# STM32U5G9 register map
File version: 1.3
CPU: CM33 r0p1, little endian, MPU, FPU, 4 interrupt priority bits
Registers are 32-bit, read-write, reset 0x0 unless marked. A register's access mark holds for its fields unless they carry their own. Offsets are from the block's base; [hi:lo] are bit positions; {n}, {i} and the like mark numbered series.

## JPEG (part 2 of 3) — JPEG address block description
Base 0x4002A000
Same registers: SEC_JPEG 0x5002A000
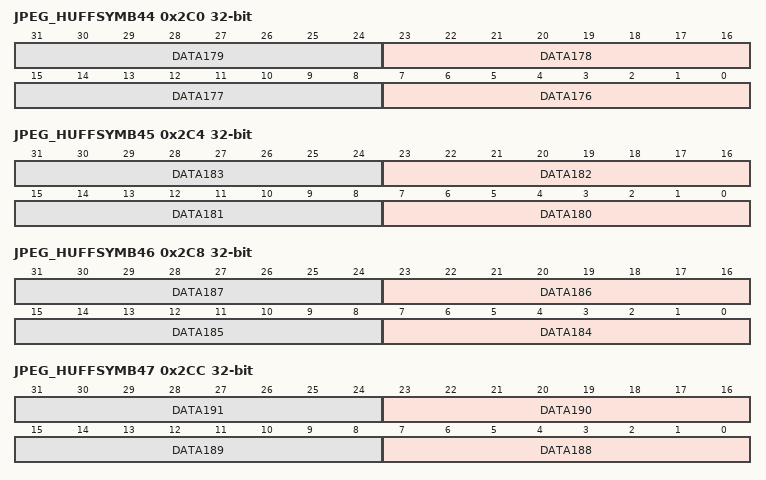
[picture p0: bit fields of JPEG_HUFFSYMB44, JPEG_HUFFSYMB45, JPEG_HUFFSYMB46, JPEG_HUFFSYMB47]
0x2C0 JPEG_HUFFSYMB44 reset not defined — This memory stores the Huffman symbols used internally by the JPEG decoder. The memory content is written by hardware during the header parsing: - DATA0 to DATA161: AC0 symbols - DATA162 to DATA173: DC0 and DC1 symbols - DATA174 to DATA335: AC1 symbols
  [8n-1401:8n-1408] DATA{n} (n=176..179) — Data {n} Huffman symbol.
0x2C4 JPEG_HUFFSYMB45 reset not defined — This memory stores the Huffman symbols used internally by the JPEG decoder. The memory content is written by hardware during the header parsing: - DATA0 to DATA161: AC0 symbols - DATA162 to DATA173: DC0 and DC1 symbols - DATA174 to DATA335: AC1 symbols
  [8n-1433:8n-1440] DATA{n} (n=180..183) — Data {n} Huffman symbol.
0x2C8 JPEG_HUFFSYMB46 reset not defined — This memory stores the Huffman symbols used internally by the JPEG decoder. The memory content is written by hardware during the header parsing: - DATA0 to DATA161: AC0 symbols - DATA162 to DATA173: DC0 and DC1 symbols - DATA174 to DATA335: AC1 symbols
  [8n-1465:8n-1472] DATA{n} (n=184..187) — Data {n} Huffman symbol.
0x2CC JPEG_HUFFSYMB47 reset not defined — This memory stores the Huffman symbols used internally by the JPEG decoder. The memory content is written by hardware during the header parsing: - DATA0 to DATA161: AC0 symbols - DATA162 to DATA173: DC0 and DC1 symbols - DATA174 to DATA335: AC1 symbols
  [8n-1497:8n-1504] DATA{n} (n=188..191) — Data {n} Huffman symbol.
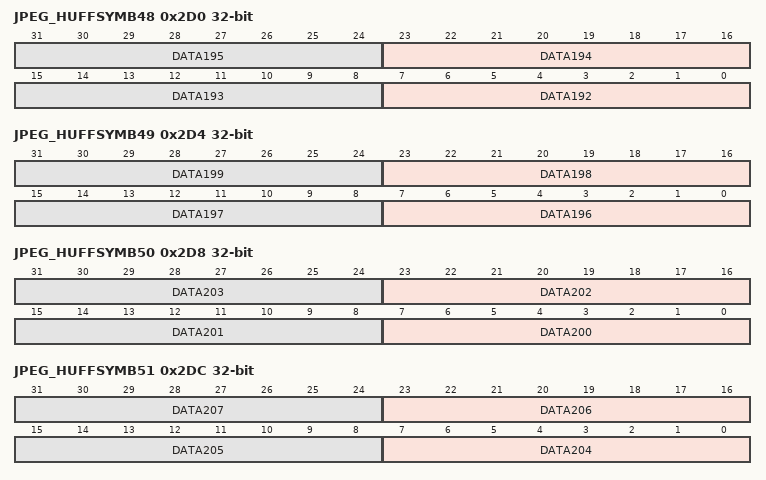
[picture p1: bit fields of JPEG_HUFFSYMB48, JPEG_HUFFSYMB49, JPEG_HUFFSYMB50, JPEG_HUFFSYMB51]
0x2D0 JPEG_HUFFSYMB48 reset not defined — This memory stores the Huffman symbols used internally by the JPEG decoder. The memory content is written by hardware during the header parsing: - DATA0 to DATA161: AC0 symbols - DATA162 to DATA173: DC0 and DC1 symbols - DATA174 to DATA335: AC1 symbols
  [8n-1529:8n-1536] DATA{n} (n=192..195) — Data {n} Huffman symbol.
0x2D4 JPEG_HUFFSYMB49 reset not defined — This memory stores the Huffman symbols used internally by the JPEG decoder. The memory content is written by hardware during the header parsing: - DATA0 to DATA161: AC0 symbols - DATA162 to DATA173: DC0 and DC1 symbols - DATA174 to DATA335: AC1 symbols
  [8n-1561:8n-1568] DATA{n} (n=196..199) — Data {n} Huffman symbol.
0x2D8 JPEG_HUFFSYMB50 reset not defined — This memory stores the Huffman symbols used internally by the JPEG decoder. The memory content is written by hardware during the header parsing: - DATA0 to DATA161: AC0 symbols - DATA162 to DATA173: DC0 and DC1 symbols - DATA174 to DATA335: AC1 symbols
  [8n-1593:8n-1600] DATA{n} (n=200..203) — Data {n} Huffman symbol.
0x2DC JPEG_HUFFSYMB51 reset not defined — This memory stores the Huffman symbols used internally by the JPEG decoder. The memory content is written by hardware during the header parsing: - DATA0 to DATA161: AC0 symbols - DATA162 to DATA173: DC0 and DC1 symbols - DATA174 to DATA335: AC1 symbols
  [8n-1625:8n-1632] DATA{n} (n=204..207) — Data {n} Huffman symbol.
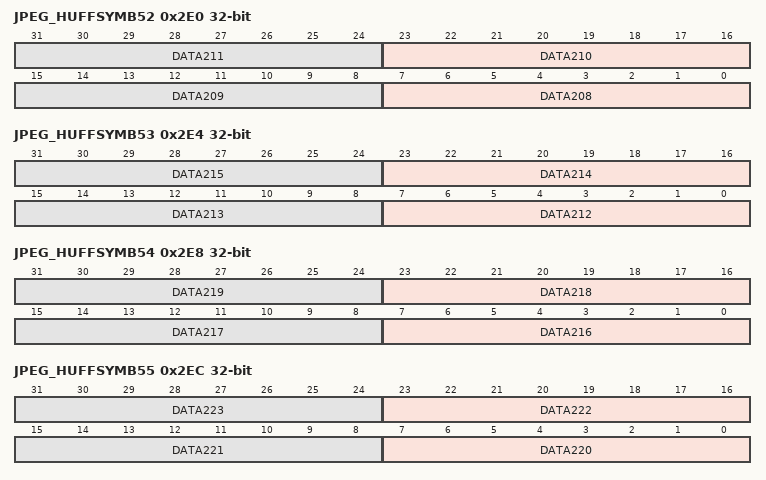
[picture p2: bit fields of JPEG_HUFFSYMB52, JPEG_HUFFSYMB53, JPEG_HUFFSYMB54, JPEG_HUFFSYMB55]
0x2E0 JPEG_HUFFSYMB52 reset not defined — This memory stores the Huffman symbols used internally by the JPEG decoder. The memory content is written by hardware during the header parsing: - DATA0 to DATA161: AC0 symbols - DATA162 to DATA173: DC0 and DC1 symbols - DATA174 to DATA335: AC1 symbols
  [8n-1657:8n-1664] DATA{n} (n=208..211) — Data {n} Huffman symbol.
0x2E4 JPEG_HUFFSYMB53 reset not defined — This memory stores the Huffman symbols used internally by the JPEG decoder. The memory content is written by hardware during the header parsing: - DATA0 to DATA161: AC0 symbols - DATA162 to DATA173: DC0 and DC1 symbols - DATA174 to DATA335: AC1 symbols
  [8n-1689:8n-1696] DATA{n} (n=212..215) — Data {n} Huffman symbol.
0x2E8 JPEG_HUFFSYMB54 reset not defined — This memory stores the Huffman symbols used internally by the JPEG decoder. The memory content is written by hardware during the header parsing: - DATA0 to DATA161: AC0 symbols - DATA162 to DATA173: DC0 and DC1 symbols - DATA174 to DATA335: AC1 symbols
  [8n-1721:8n-1728] DATA{n} (n=216..219) — Data {n} Huffman symbol.
0x2EC JPEG_HUFFSYMB55 reset not defined — This memory stores the Huffman symbols used internally by the JPEG decoder. The memory content is written by hardware during the header parsing: - DATA0 to DATA161: AC0 symbols - DATA162 to DATA173: DC0 and DC1 symbols - DATA174 to DATA335: AC1 symbols
  [8n-1753:8n-1760] DATA{n} (n=220..223) — Data {n} Huffman symbol.
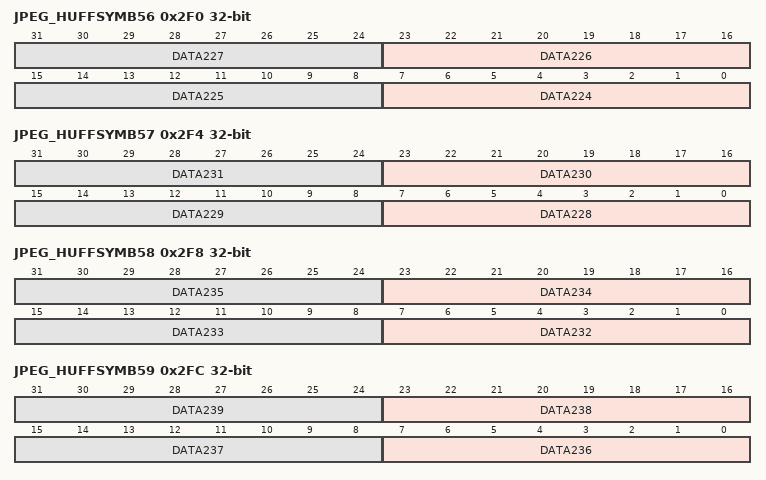
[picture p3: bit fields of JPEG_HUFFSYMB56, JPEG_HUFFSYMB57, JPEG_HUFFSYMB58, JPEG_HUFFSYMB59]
0x2F0 JPEG_HUFFSYMB56 reset not defined — This memory stores the Huffman symbols used internally by the JPEG decoder. The memory content is written by hardware during the header parsing: - DATA0 to DATA161: AC0 symbols - DATA162 to DATA173: DC0 and DC1 symbols - DATA174 to DATA335: AC1 symbols
  [8n-1785:8n-1792] DATA{n} (n=224..227) — Data {n} Huffman symbol.
0x2F4 JPEG_HUFFSYMB57 reset not defined — This memory stores the Huffman symbols used internally by the JPEG decoder. The memory content is written by hardware during the header parsing: - DATA0 to DATA161: AC0 symbols - DATA162 to DATA173: DC0 and DC1 symbols - DATA174 to DATA335: AC1 symbols
  [8n-1817:8n-1824] DATA{n} (n=228..231) — Data {n} Huffman symbol.
0x2F8 JPEG_HUFFSYMB58 reset not defined — This memory stores the Huffman symbols used internally by the JPEG decoder. The memory content is written by hardware during the header parsing: - DATA0 to DATA161: AC0 symbols - DATA162 to DATA173: DC0 and DC1 symbols - DATA174 to DATA335: AC1 symbols
  [8n-1849:8n-1856] DATA{n} (n=232..235) — Data {n} Huffman symbol.
0x2FC JPEG_HUFFSYMB59 reset not defined — This memory stores the Huffman symbols used internally by the JPEG decoder. The memory content is written by hardware during the header parsing: - DATA0 to DATA161: AC0 symbols - DATA162 to DATA173: DC0 and DC1 symbols - DATA174 to DATA335: AC1 symbols
  [8n-1881:8n-1888] DATA{n} (n=236..239) — Data {n} Huffman symbol.
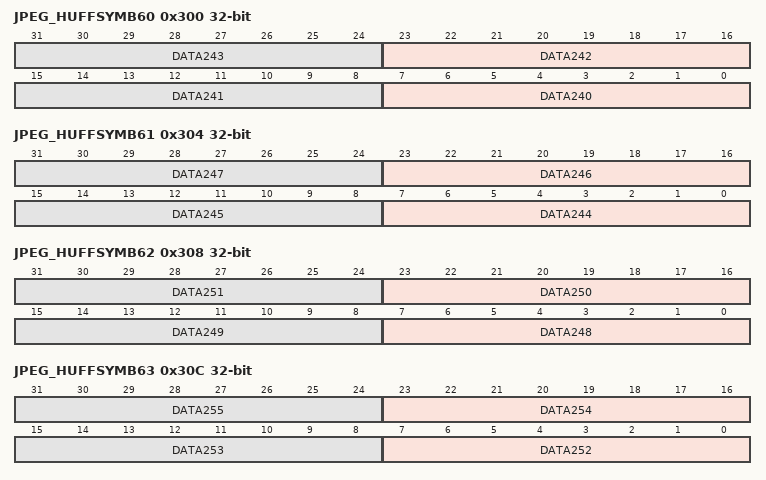
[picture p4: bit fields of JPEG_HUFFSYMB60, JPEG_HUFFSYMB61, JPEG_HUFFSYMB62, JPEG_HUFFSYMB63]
0x300 JPEG_HUFFSYMB60 reset not defined — This memory stores the Huffman symbols used internally by the JPEG decoder. The memory content is written by hardware during the header parsing: - DATA0 to DATA161: AC0 symbols - DATA162 to DATA173: DC0 and DC1 symbols - DATA174 to DATA335: AC1 symbols
  [8n-1913:8n-1920] DATA{n} (n=240..243) — Data {n} Huffman symbol.
0x304 JPEG_HUFFSYMB61 reset not defined — This memory stores the Huffman symbols used internally by the JPEG decoder. The memory content is written by hardware during the header parsing: - DATA0 to DATA161: AC0 symbols - DATA162 to DATA173: DC0 and DC1 symbols - DATA174 to DATA335: AC1 symbols
  [8n-1945:8n-1952] DATA{n} (n=244..247) — Data {n} Huffman symbol.
0x308 JPEG_HUFFSYMB62 reset not defined — This memory stores the Huffman symbols used internally by the JPEG decoder. The memory content is written by hardware during the header parsing: - DATA0 to DATA161: AC0 symbols - DATA162 to DATA173: DC0 and DC1 symbols - DATA174 to DATA335: AC1 symbols
  [8n-1977:8n-1984] DATA{n} (n=248..251) — Data {n} Huffman symbol.
0x30C JPEG_HUFFSYMB63 reset not defined — This memory stores the Huffman symbols used internally by the JPEG decoder. The memory content is written by hardware during the header parsing: - DATA0 to DATA161: AC0 symbols - DATA162 to DATA173: DC0 and DC1 symbols - DATA174 to DATA335: AC1 symbols
  [8n-2009:8n-2016] DATA{n} (n=252..255) — Data {n} Huffman symbol.
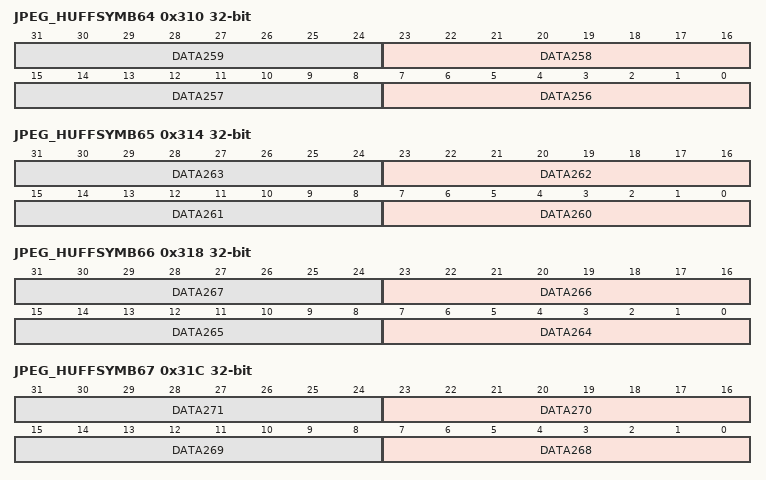
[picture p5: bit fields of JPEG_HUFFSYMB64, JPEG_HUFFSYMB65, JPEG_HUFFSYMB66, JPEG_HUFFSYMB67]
0x310 JPEG_HUFFSYMB64 reset not defined — This memory stores the Huffman symbols used internally by the JPEG decoder. The memory content is written by hardware during the header parsing: - DATA0 to DATA161: AC0 symbols - DATA162 to DATA173: DC0 and DC1 symbols - DATA174 to DATA335: AC1 symbols
  [8n-2041:8n-2048] DATA{n} (n=256..259) — Data {n} Huffman symbol.
0x314 JPEG_HUFFSYMB65 reset not defined — This memory stores the Huffman symbols used internally by the JPEG decoder. The memory content is written by hardware during the header parsing: - DATA0 to DATA161: AC0 symbols - DATA162 to DATA173: DC0 and DC1 symbols - DATA174 to DATA335: AC1 symbols
  [8n-2073:8n-2080] DATA{n} (n=260..263) — Data {n} Huffman symbol.
0x318 JPEG_HUFFSYMB66 reset not defined — This memory stores the Huffman symbols used internally by the JPEG decoder. The memory content is written by hardware during the header parsing: - DATA0 to DATA161: AC0 symbols - DATA162 to DATA173: DC0 and DC1 symbols - DATA174 to DATA335: AC1 symbols
  [8n-2105:8n-2112] DATA{n} (n=264..267) — Data {n} Huffman symbol.
0x31C JPEG_HUFFSYMB67 reset not defined — This memory stores the Huffman symbols used internally by the JPEG decoder. The memory content is written by hardware during the header parsing: - DATA0 to DATA161: AC0 symbols - DATA162 to DATA173: DC0 and DC1 symbols - DATA174 to DATA335: AC1 symbols
  [8n-2137:8n-2144] DATA{n} (n=268..271) — Data {n} Huffman symbol.
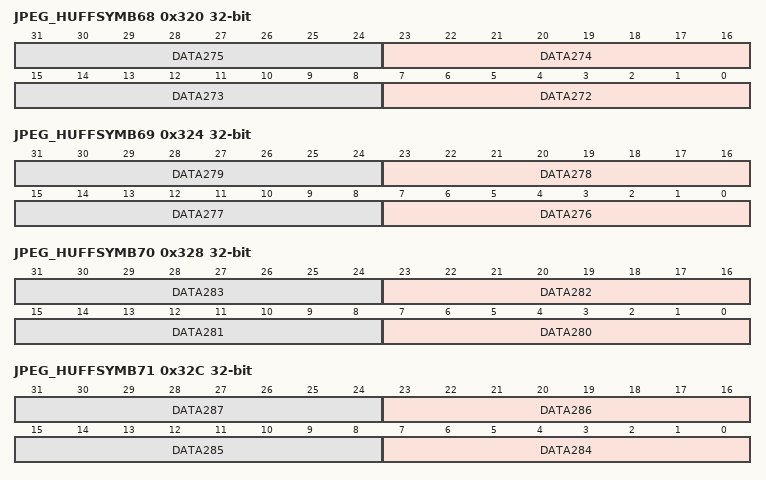
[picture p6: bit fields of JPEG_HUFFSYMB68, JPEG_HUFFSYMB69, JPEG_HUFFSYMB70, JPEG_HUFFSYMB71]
0x320 JPEG_HUFFSYMB68 reset not defined — This memory stores the Huffman symbols used internally by the JPEG decoder. The memory content is written by hardware during the header parsing: - DATA0 to DATA161: AC0 symbols - DATA162 to DATA173: DC0 and DC1 symbols - DATA174 to DATA335: AC1 symbols
  [8n-2169:8n-2176] DATA{n} (n=272..275) — Data {n} Huffman symbol.
0x324 JPEG_HUFFSYMB69 reset not defined — This memory stores the Huffman symbols used internally by the JPEG decoder. The memory content is written by hardware during the header parsing: - DATA0 to DATA161: AC0 symbols - DATA162 to DATA173: DC0 and DC1 symbols - DATA174 to DATA335: AC1 symbols
  [8n-2201:8n-2208] DATA{n} (n=276..279) — Data {n} Huffman symbol.
0x328 JPEG_HUFFSYMB70 reset not defined — This memory stores the Huffman symbols used internally by the JPEG decoder. The memory content is written by hardware during the header parsing: - DATA0 to DATA161: AC0 symbols - DATA162 to DATA173: DC0 and DC1 symbols - DATA174 to DATA335: AC1 symbols
  [8n-2233:8n-2240] DATA{n} (n=280..283) — Data {n} Huffman symbol.
0x32C JPEG_HUFFSYMB71 reset not defined — This memory stores the Huffman symbols used internally by the JPEG decoder. The memory content is written by hardware during the header parsing: - DATA0 to DATA161: AC0 symbols - DATA162 to DATA173: DC0 and DC1 symbols - DATA174 to DATA335: AC1 symbols
  [8n-2265:8n-2272] DATA{n} (n=284..287) — Data {n} Huffman symbol.
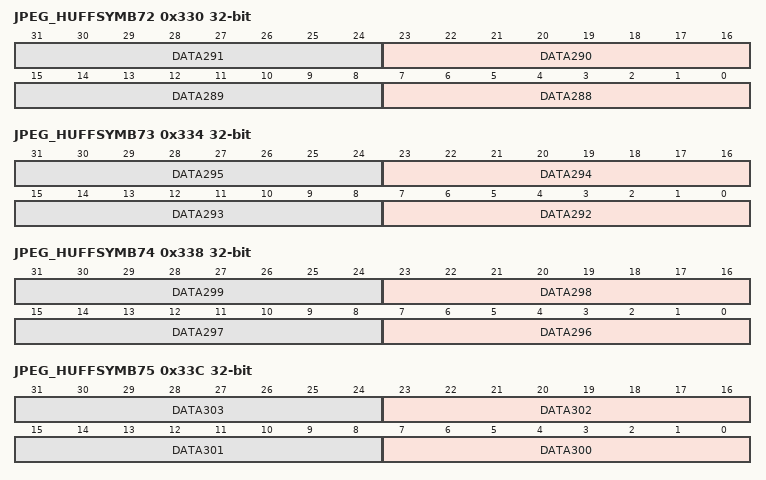
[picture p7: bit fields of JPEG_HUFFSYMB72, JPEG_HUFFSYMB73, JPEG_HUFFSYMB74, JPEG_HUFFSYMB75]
0x330 JPEG_HUFFSYMB72 reset not defined — This memory stores the Huffman symbols used internally by the JPEG decoder. The memory content is written by hardware during the header parsing: - DATA0 to DATA161: AC0 symbols - DATA162 to DATA173: DC0 and DC1 symbols - DATA174 to DATA335: AC1 symbols
  [8n-2297:8n-2304] DATA{n} (n=288..291) — Data {n} Huffman symbol.
0x334 JPEG_HUFFSYMB73 reset not defined — This memory stores the Huffman symbols used internally by the JPEG decoder. The memory content is written by hardware during the header parsing: - DATA0 to DATA161: AC0 symbols - DATA162 to DATA173: DC0 and DC1 symbols - DATA174 to DATA335: AC1 symbols
  [8n-2329:8n-2336] DATA{n} (n=292..295) — Data {n} Huffman symbol.
0x338 JPEG_HUFFSYMB74 reset not defined — This memory stores the Huffman symbols used internally by the JPEG decoder. The memory content is written by hardware during the header parsing: - DATA0 to DATA161: AC0 symbols - DATA162 to DATA173: DC0 and DC1 symbols - DATA174 to DATA335: AC1 symbols
  [8n-2361:8n-2368] DATA{n} (n=296..299) — Data {n} Huffman symbol.
0x33C JPEG_HUFFSYMB75 reset not defined — This memory stores the Huffman symbols used internally by the JPEG decoder. The memory content is written by hardware during the header parsing: - DATA0 to DATA161: AC0 symbols - DATA162 to DATA173: DC0 and DC1 symbols - DATA174 to DATA335: AC1 symbols
  [8n-2393:8n-2400] DATA{n} (n=300..303) — Data {n} Huffman symbol.
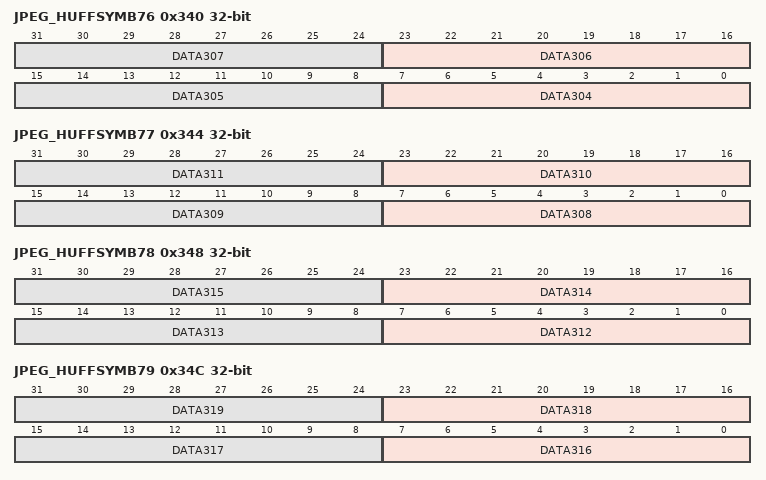
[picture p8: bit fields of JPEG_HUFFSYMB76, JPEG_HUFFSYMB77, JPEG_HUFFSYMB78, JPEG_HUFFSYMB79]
0x340 JPEG_HUFFSYMB76 reset not defined — This memory stores the Huffman symbols used internally by the JPEG decoder. The memory content is written by hardware during the header parsing: - DATA0 to DATA161: AC0 symbols - DATA162 to DATA173: DC0 and DC1 symbols - DATA174 to DATA335: AC1 symbols
  [8n-2425:8n-2432] DATA{n} (n=304..307) — Data {n} Huffman symbol.
0x344 JPEG_HUFFSYMB77 reset not defined — This memory stores the Huffman symbols used internally by the JPEG decoder. The memory content is written by hardware during the header parsing: - DATA0 to DATA161: AC0 symbols - DATA162 to DATA173: DC0 and DC1 symbols - DATA174 to DATA335: AC1 symbols
  [8n-2457:8n-2464] DATA{n} (n=308..311) — Data {n} Huffman symbol.
0x348 JPEG_HUFFSYMB78 reset not defined — This memory stores the Huffman symbols used internally by the JPEG decoder. The memory content is written by hardware during the header parsing: - DATA0 to DATA161: AC0 symbols - DATA162 to DATA173: DC0 and DC1 symbols - DATA174 to DATA335: AC1 symbols
  [8n-2489:8n-2496] DATA{n} (n=312..315) — Data {n} Huffman symbol.
0x34C JPEG_HUFFSYMB79 reset not defined — This memory stores the Huffman symbols used internally by the JPEG decoder. The memory content is written by hardware during the header parsing: - DATA0 to DATA161: AC0 symbols - DATA162 to DATA173: DC0 and DC1 symbols - DATA174 to DATA335: AC1 symbols
  [8n-2521:8n-2528] DATA{n} (n=316..319) — Data {n} Huffman symbol.
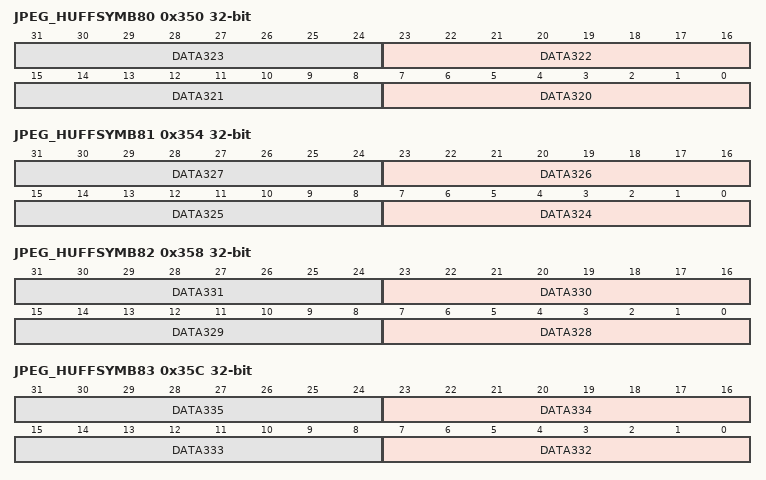
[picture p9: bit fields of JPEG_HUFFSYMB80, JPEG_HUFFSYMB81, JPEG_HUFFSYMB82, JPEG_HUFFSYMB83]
0x350 JPEG_HUFFSYMB80 reset not defined — This memory stores the Huffman symbols used internally by the JPEG decoder. The memory content is written by hardware during the header parsing: - DATA0 to DATA161: AC0 symbols - DATA162 to DATA173: DC0 and DC1 symbols - DATA174 to DATA335: AC1 symbols
  [8n-2553:8n-2560] DATA{n} (n=320..323) — Data {n} Huffman symbol.
0x354 JPEG_HUFFSYMB81 reset not defined — This memory stores the Huffman symbols used internally by the JPEG decoder. The memory content is written by hardware during the header parsing: - DATA0 to DATA161: AC0 symbols - DATA162 to DATA173: DC0 and DC1 symbols - DATA174 to DATA335: AC1 symbols
  [8n-2585:8n-2592] DATA{n} (n=324..327) — Data {n} Huffman symbol.
0x358 JPEG_HUFFSYMB82 reset not defined — This memory stores the Huffman symbols used internally by the JPEG decoder. The memory content is written by hardware during the header parsing: - DATA0 to DATA161: AC0 symbols - DATA162 to DATA173: DC0 and DC1 symbols - DATA174 to DATA335: AC1 symbols
  [8n-2617:8n-2624] DATA{n} (n=328..331) — Data {n} Huffman symbol.
0x35C JPEG_HUFFSYMB83 reset not defined — This memory stores the Huffman symbols used internally by the JPEG decoder. The memory content is written by hardware during the header parsing: - DATA0 to DATA161: AC0 symbols - DATA162 to DATA173: DC0 and DC1 symbols - DATA174 to DATA335: AC1 symbols
  [8n-2649:8n-2656] DATA{n} (n=332..335) — Data {n} Huffman symbol.
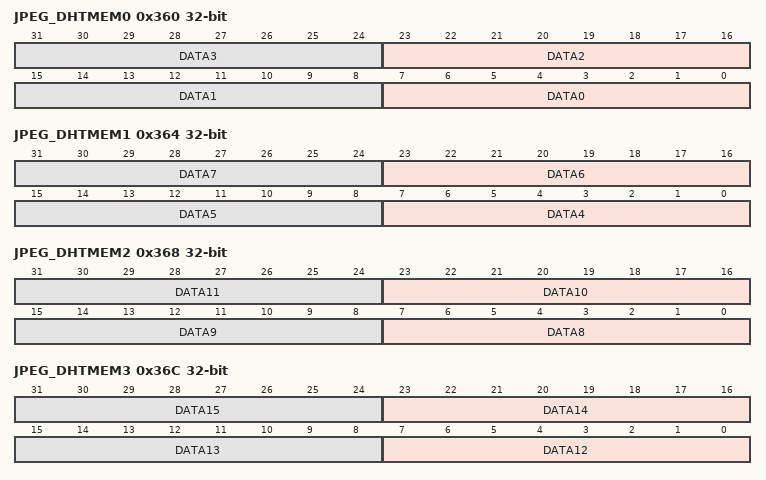
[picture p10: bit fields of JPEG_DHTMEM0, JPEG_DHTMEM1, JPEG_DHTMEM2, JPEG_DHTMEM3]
0x360 JPEG_DHTMEM0 reset not defined — For encoding process with header generation, this memory stores the DHT marker segment AC and DC Huffman tables in the ISO/IEC specification format: - DATA0 to DATA27: DC Huffman table0 - DATA28 to DATA205: AC Huffman table0 - DATA206 to DATA233: DC Huffman table1 - DATA234 to DATA411: AC Huffman table1
  [8n+7:8n] DATA{n} (n=0..3) — Huffman table data {n} Huffman table data for DHT marker segment generation.
0x364 JPEG_DHTMEM1 reset not defined — For encoding process with header generation, this memory stores the DHT marker segment AC and DC Huffman tables in the ISO/IEC specification format: - DATA0 to DATA27: DC Huffman table0 - DATA28 to DATA205: AC Huffman table0 - DATA206 to DATA233: DC Huffman table1 - DATA234 to DATA411: AC Huffman table1
  [8n-25:8n-32] DATA{n} (n=4..7) — Huffman table data {n} Huffman table data for DHT marker segment generation.
0x368 JPEG_DHTMEM2 reset not defined — For encoding process with header generation, this memory stores the DHT marker segment AC and DC Huffman tables in the ISO/IEC specification format: - DATA0 to DATA27: DC Huffman table0 - DATA28 to DATA205: AC Huffman table0 - DATA206 to DATA233: DC Huffman table1 - DATA234 to DATA411: AC Huffman table1
  [8n-57:8n-64] DATA{n} (n=8..11) — Huffman table data {n} Huffman table data for DHT marker segment generation.
0x36C JPEG_DHTMEM3 reset not defined — For encoding process with header generation, this memory stores the DHT marker segment AC and DC Huffman tables in the ISO/IEC specification format: - DATA0 to DATA27: DC Huffman table0 - DATA28 to DATA205: AC Huffman table0 - DATA206 to DATA233: DC Huffman table1 - DATA234 to DATA411: AC Huffman table1
  [8n-89:8n-96] DATA{n} (n=12..15) — Huffman table data {n} Huffman table data for DHT marker segment generation.
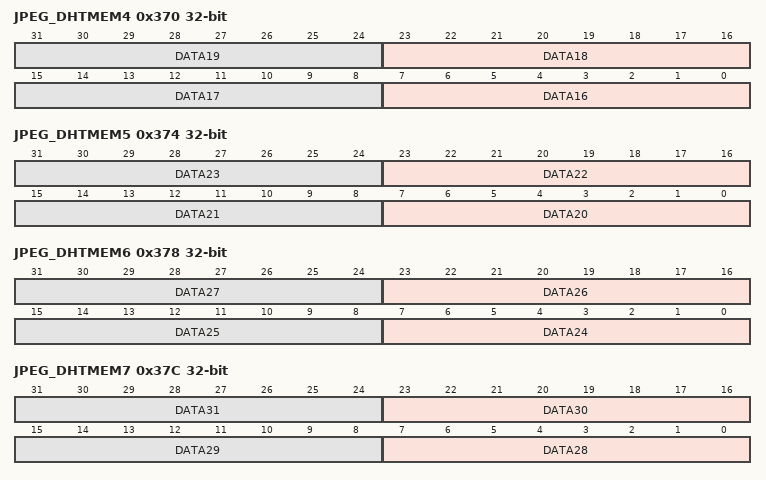
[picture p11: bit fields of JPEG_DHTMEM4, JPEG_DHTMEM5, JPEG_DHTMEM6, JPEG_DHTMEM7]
0x370 JPEG_DHTMEM4 reset not defined — For encoding process with header generation, this memory stores the DHT marker segment AC and DC Huffman tables in the ISO/IEC specification format: - DATA0 to DATA27: DC Huffman table0 - DATA28 to DATA205: AC Huffman table0 - DATA206 to DATA233: DC Huffman table1 - DATA234 to DATA411: AC Huffman table1
  [8n-121:8n-128] DATA{n} (n=16..19) — Huffman table data {n} Huffman table data for DHT marker segment generation.
0x374 JPEG_DHTMEM5 reset not defined — For encoding process with header generation, this memory stores the DHT marker segment AC and DC Huffman tables in the ISO/IEC specification format: - DATA0 to DATA27: DC Huffman table0 - DATA28 to DATA205: AC Huffman table0 - DATA206 to DATA233: DC Huffman table1 - DATA234 to DATA411: AC Huffman table1
  [8n-153:8n-160] DATA{n} (n=20..23) — Huffman table data {n} Huffman table data for DHT marker segment generation.
0x378 JPEG_DHTMEM6 reset not defined — For encoding process with header generation, this memory stores the DHT marker segment AC and DC Huffman tables in the ISO/IEC specification format: - DATA0 to DATA27: DC Huffman table0 - DATA28 to DATA205: AC Huffman table0 - DATA206 to DATA233: DC Huffman table1 - DATA234 to DATA411: AC Huffman table1
  [8n-185:8n-192] DATA{n} (n=24..27) — Huffman table data {n} Huffman table data for DHT marker segment generation.
0x37C JPEG_DHTMEM7 reset not defined — For encoding process with header generation, this memory stores the DHT marker segment AC and DC Huffman tables in the ISO/IEC specification format: - DATA0 to DATA27: DC Huffman table0 - DATA28 to DATA205: AC Huffman table0 - DATA206 to DATA233: DC Huffman table1 - DATA234 to DATA411: AC Huffman table1
  [8n-217:8n-224] DATA{n} (n=28..31) — Huffman table data {n} Huffman table data for DHT marker segment generation.
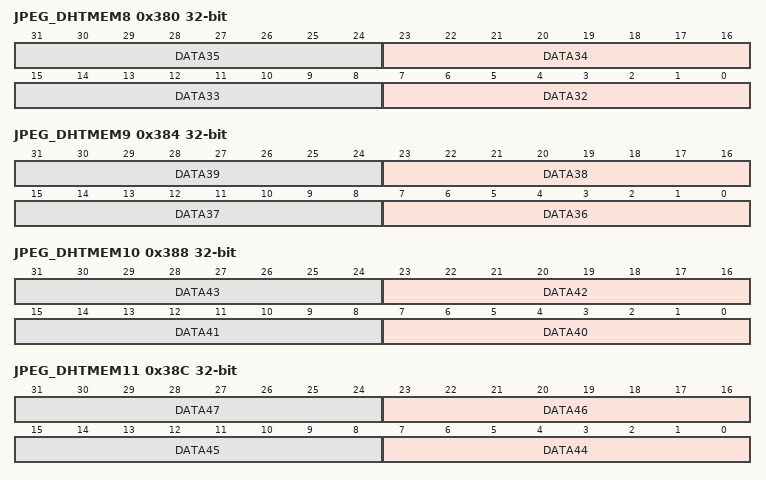
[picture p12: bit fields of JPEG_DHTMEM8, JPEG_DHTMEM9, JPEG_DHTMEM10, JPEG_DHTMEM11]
0x380 JPEG_DHTMEM8 reset not defined — For encoding process with header generation, this memory stores the DHT marker segment AC and DC Huffman tables in the ISO/IEC specification format: - DATA0 to DATA27: DC Huffman table0 - DATA28 to DATA205: AC Huffman table0 - DATA206 to DATA233: DC Huffman table1 - DATA234 to DATA411: AC Huffman table1
  [8n-249:8n-256] DATA{n} (n=32..35) — Huffman table data {n} Huffman table data for DHT marker segment generation.
0x384 JPEG_DHTMEM9 reset not defined — For encoding process with header generation, this memory stores the DHT marker segment AC and DC Huffman tables in the ISO/IEC specification format: - DATA0 to DATA27: DC Huffman table0 - DATA28 to DATA205: AC Huffman table0 - DATA206 to DATA233: DC Huffman table1 - DATA234 to DATA411: AC Huffman table1
  [8n-281:8n-288] DATA{n} (n=36..39) — Huffman table data {n} Huffman table data for DHT marker segment generation.
0x388 JPEG_DHTMEM10 reset not defined — For encoding process with header generation, this memory stores the DHT marker segment AC and DC Huffman tables in the ISO/IEC specification format: - DATA0 to DATA27: DC Huffman table0 - DATA28 to DATA205: AC Huffman table0 - DATA206 to DATA233: DC Huffman table1 - DATA234 to DATA411: AC Huffman table1
  [8n-313:8n-320] DATA{n} (n=40..43) — Huffman table data {n} Huffman table data for DHT marker segment generation.
0x38C JPEG_DHTMEM11 reset not defined — For encoding process with header generation, this memory stores the DHT marker segment AC and DC Huffman tables in the ISO/IEC specification format: - DATA0 to DATA27: DC Huffman table0 - DATA28 to DATA205: AC Huffman table0 - DATA206 to DATA233: DC Huffman table1 - DATA234 to DATA411: AC Huffman table1
  [8n-345:8n-352] DATA{n} (n=44..47) — Huffman table data {n} Huffman table data for DHT marker segment generation.
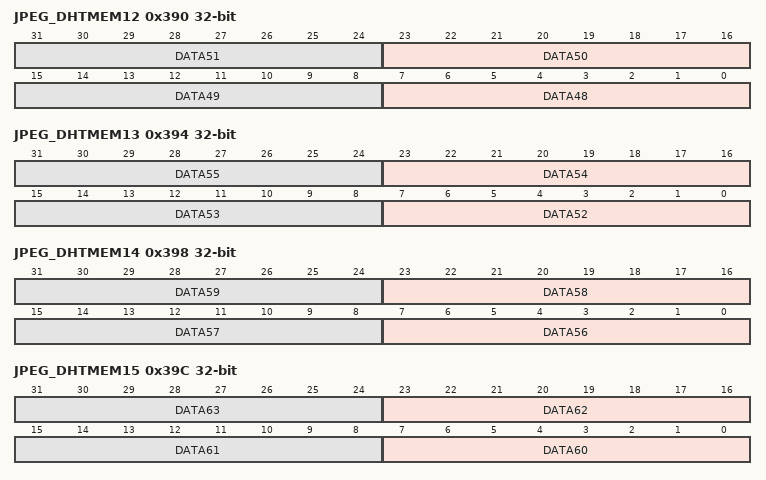
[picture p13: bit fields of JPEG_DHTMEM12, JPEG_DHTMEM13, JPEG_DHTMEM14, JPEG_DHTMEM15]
0x390 JPEG_DHTMEM12 reset not defined — For encoding process with header generation, this memory stores the DHT marker segment AC and DC Huffman tables in the ISO/IEC specification format: - DATA0 to DATA27: DC Huffman table0 - DATA28 to DATA205: AC Huffman table0 - DATA206 to DATA233: DC Huffman table1 - DATA234 to DATA411: AC Huffman table1
  [8n-377:8n-384] DATA{n} (n=48..51) — Huffman table data {n} Huffman table data for DHT marker segment generation.
0x394 JPEG_DHTMEM13 reset not defined — For encoding process with header generation, this memory stores the DHT marker segment AC and DC Huffman tables in the ISO/IEC specification format: - DATA0 to DATA27: DC Huffman table0 - DATA28 to DATA205: AC Huffman table0 - DATA206 to DATA233: DC Huffman table1 - DATA234 to DATA411: AC Huffman table1
  [8n-409:8n-416] DATA{n} (n=52..55) — Huffman table data {n} Huffman table data for DHT marker segment generation.
0x398 JPEG_DHTMEM14 reset not defined — For encoding process with header generation, this memory stores the DHT marker segment AC and DC Huffman tables in the ISO/IEC specification format: - DATA0 to DATA27: DC Huffman table0 - DATA28 to DATA205: AC Huffman table0 - DATA206 to DATA233: DC Huffman table1 - DATA234 to DATA411: AC Huffman table1
  [8n-441:8n-448] DATA{n} (n=56..59) — Huffman table data {n} Huffman table data for DHT marker segment generation.
0x39C JPEG_DHTMEM15 reset not defined — For encoding process with header generation, this memory stores the DHT marker segment AC and DC Huffman tables in the ISO/IEC specification format: - DATA0 to DATA27: DC Huffman table0 - DATA28 to DATA205: AC Huffman table0 - DATA206 to DATA233: DC Huffman table1 - DATA234 to DATA411: AC Huffman table1
  [8n-473:8n-480] DATA{n} (n=60..63) — Huffman table data {n} Huffman table data for DHT marker segment generation.
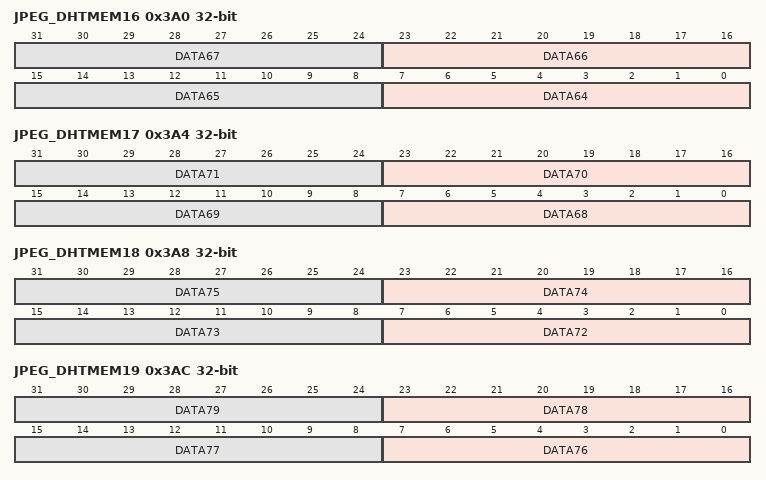
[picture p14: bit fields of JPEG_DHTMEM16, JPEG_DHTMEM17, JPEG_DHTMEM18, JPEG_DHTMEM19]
0x3A0 JPEG_DHTMEM16 reset not defined — For encoding process with header generation, this memory stores the DHT marker segment AC and DC Huffman tables in the ISO/IEC specification format: - DATA0 to DATA27: DC Huffman table0 - DATA28 to DATA205: AC Huffman table0 - DATA206 to DATA233: DC Huffman table1 - DATA234 to DATA411: AC Huffman table1
  [8n-505:8n-512] DATA{n} (n=64..67) — Huffman table data {n} Huffman table data for DHT marker segment generation.
0x3A4 JPEG_DHTMEM17 reset not defined — For encoding process with header generation, this memory stores the DHT marker segment AC and DC Huffman tables in the ISO/IEC specification format: - DATA0 to DATA27: DC Huffman table0 - DATA28 to DATA205: AC Huffman table0 - DATA206 to DATA233: DC Huffman table1 - DATA234 to DATA411: AC Huffman table1
  [8n-537:8n-544] DATA{n} (n=68..71) — Huffman table data {n} Huffman table data for DHT marker segment generation.
0x3A8 JPEG_DHTMEM18 reset not defined — For encoding process with header generation, this memory stores the DHT marker segment AC and DC Huffman tables in the ISO/IEC specification format: - DATA0 to DATA27: DC Huffman table0 - DATA28 to DATA205: AC Huffman table0 - DATA206 to DATA233: DC Huffman table1 - DATA234 to DATA411: AC Huffman table1
  [8n-569:8n-576] DATA{n} (n=72..75) — Huffman table data {n} Huffman table data for DHT marker segment generation.
0x3AC JPEG_DHTMEM19 reset not defined — For encoding process with header generation, this memory stores the DHT marker segment AC and DC Huffman tables in the ISO/IEC specification format: - DATA0 to DATA27: DC Huffman table0 - DATA28 to DATA205: AC Huffman table0 - DATA206 to DATA233: DC Huffman table1 - DATA234 to DATA411: AC Huffman table1
  [8n-601:8n-608] DATA{n} (n=76..79) — Huffman table data {n} Huffman table data for DHT marker segment generation.
0x3B0 JPEG_DHTMEM20 reset not defined — For encoding process with header generation, this memory stores the DHT marker segment AC and DC Huffman tables in the ISO/IEC specification format: - DATA0 to DATA27: DC Huffman table0 - DATA28 to DATA205: AC Huffman table0 - DATA206 to DATA233: DC Huffman table1 - DATA234 to DATA411: AC Huffman table1
  [8n-633:8n-640] DATA{n} (n=80..83) — Huffman table data {n} Huffman table data for DHT marker segment generation.
0x3B4 JPEG_DHTMEM21 reset not defined — For encoding process with header generation, this memory stores the DHT marker segment AC and DC Huffman tables in the ISO/IEC specification format: - DATA0 to DATA27: DC Huffman table0 - DATA28 to DATA205: AC Huffman table0 - DATA206 to DATA233: DC Huffman table1 - DATA234 to DATA411: AC Huffman table1
  [8n-665:8n-672] DATA{n} (n=84..87) — Huffman table data {n} Huffman table data for DHT marker segment generation.
0x3B8 JPEG_DHTMEM22 reset not defined — For encoding process with header generation, this memory stores the DHT marker segment AC and DC Huffman tables in the ISO/IEC specification format: - DATA0 to DATA27: DC Huffman table0 - DATA28 to DATA205: AC Huffman table0 - DATA206 to DATA233: DC Huffman table1 - DATA234 to DATA411: AC Huffman table1
  [8n-697:8n-704] DATA{n} (n=88..91) — Huffman table data {n} Huffman table data for DHT marker segment generation.
0x3BC JPEG_DHTMEM23 reset not defined — For encoding process with header generation, this memory stores the DHT marker segment AC and DC Huffman tables in the ISO/IEC specification format: - DATA0 to DATA27: DC Huffman table0 - DATA28 to DATA205: AC Huffman table0 - DATA206 to DATA233: DC Huffman table1 - DATA234 to DATA411: AC Huffman table1
  [8n-729:8n-736] DATA{n} (n=92..95) — Huffman table data {n} Huffman table data for DHT marker segment generation.
0x3C0 JPEG_DHTMEM24 reset not defined — For encoding process with header generation, this memory stores the DHT marker segment AC and DC Huffman tables in the ISO/IEC specification format: - DATA0 to DATA27: DC Huffman table0 - DATA28 to DATA205: AC Huffman table0 - DATA206 to DATA233: DC Huffman table1 - DATA234 to DATA411: AC Huffman table1
  [8n-761:8n-768] DATA{n} (n=96..99) — Huffman table data {n} Huffman table data for DHT marker segment generation.
0x3C4 JPEG_DHTMEM25 reset not defined — For encoding process with header generation, this memory stores the DHT marker segment AC and DC Huffman tables in the ISO/IEC specification format: - DATA0 to DATA27: DC Huffman table0 - DATA28 to DATA205: AC Huffman table0 - DATA206 to DATA233: DC Huffman table1 - DATA234 to DATA411: AC Huffman table1
  [8n-793:8n-800] DATA{n} (n=100..103) — Huffman table data {n} Huffman table data for DHT marker segment generation.
0x3C8 JPEG_DHTMEM26 reset not defined — For encoding process with header generation, this memory stores the DHT marker segment AC and DC Huffman tables in the ISO/IEC specification format: - DATA0 to DATA27: DC Huffman table0 - DATA28 to DATA205: AC Huffman table0 - DATA206 to DATA233: DC Huffman table1 - DATA234 to DATA411: AC Huffman table1
  [8n-825:8n-832] DATA{n} (n=104..107) — Huffman table data {n} Huffman table data for DHT marker segment generation.
0x3CC JPEG_DHTMEM27 reset not defined — For encoding process with header generation, this memory stores the DHT marker segment AC and DC Huffman tables in the ISO/IEC specification format: - DATA0 to DATA27: DC Huffman table0 - DATA28 to DATA205: AC Huffman table0 - DATA206 to DATA233: DC Huffman table1 - DATA234 to DATA411: AC Huffman table1
  [8n-857:8n-864] DATA{n} (n=108..111) — Huffman table data {n} Huffman table data for DHT marker segment generation.
0x3D0 JPEG_DHTMEM28 reset not defined — For encoding process with header generation, this memory stores the DHT marker segment AC and DC Huffman tables in the ISO/IEC specification format: - DATA0 to DATA27: DC Huffman table0 - DATA28 to DATA205: AC Huffman table0 - DATA206 to DATA233: DC Huffman table1 - DATA234 to DATA411: AC Huffman table1
  [8n-889:8n-896] DATA{n} (n=112..115) — Huffman table data {n} Huffman table data for DHT marker segment generation.
0x3D4 JPEG_DHTMEM29 reset not defined — For encoding process with header generation, this memory stores the DHT marker segment AC and DC Huffman tables in the ISO/IEC specification format: - DATA0 to DATA27: DC Huffman table0 - DATA28 to DATA205: AC Huffman table0 - DATA206 to DATA233: DC Huffman table1 - DATA234 to DATA411: AC Huffman table1
  [8n-921:8n-928] DATA{n} (n=116..119) — Huffman table data {n} Huffman table data for DHT marker segment generation.
0x3D8 JPEG_DHTMEM30 reset not defined — For encoding process with header generation, this memory stores the DHT marker segment AC and DC Huffman tables in the ISO/IEC specification format: - DATA0 to DATA27: DC Huffman table0 - DATA28 to DATA205: AC Huffman table0 - DATA206 to DATA233: DC Huffman table1 - DATA234 to DATA411: AC Huffman table1
  [8n-953:8n-960] DATA{n} (n=120..123) — Huffman table data {n} Huffman table data for DHT marker segment generation.
0x3DC JPEG_DHTMEM31 reset not defined — For encoding process with header generation, this memory stores the DHT marker segment AC and DC Huffman tables in the ISO/IEC specification format: - DATA0 to DATA27: DC Huffman table0 - DATA28 to DATA205: AC Huffman table0 - DATA206 to DATA233: DC Huffman table1 - DATA234 to DATA411: AC Huffman table1
  [8n-985:8n-992] DATA{n} (n=124..127) — Huffman table data {n} Huffman table data for DHT marker segment generation.
0x3E0 JPEG_DHTMEM32 reset not defined — For encoding process with header generation, this memory stores the DHT marker segment AC and DC Huffman tables in the ISO/IEC specification format: - DATA0 to DATA27: DC Huffman table0 - DATA28 to DATA205: AC Huffman table0 - DATA206 to DATA233: DC Huffman table1 - DATA234 to DATA411: AC Huffman table1
  [8n-1017:8n-1024] DATA{n} (n=128..131) — Huffman table data {n} Huffman table data for DHT marker segment generation.
0x3E4 JPEG_DHTMEM33 reset not defined — For encoding process with header generation, this memory stores the DHT marker segment AC and DC Huffman tables in the ISO/IEC specification format: - DATA0 to DATA27: DC Huffman table0 - DATA28 to DATA205: AC Huffman table0 - DATA206 to DATA233: DC Huffman table1 - DATA234 to DATA411: AC Huffman table1
  [8n-1049:8n-1056] DATA{n} (n=132..135) — Huffman table data {n} Huffman table data for DHT marker segment generation.
0x3E8 JPEG_DHTMEM34 reset not defined — For encoding process with header generation, this memory stores the DHT marker segment AC and DC Huffman tables in the ISO/IEC specification format: - DATA0 to DATA27: DC Huffman table0 - DATA28 to DATA205: AC Huffman table0 - DATA206 to DATA233: DC Huffman table1 - DATA234 to DATA411: AC Huffman table1
  [8n-1081:8n-1088] DATA{n} (n=136..139) — Huffman table data {n} Huffman table data for DHT marker segment generation.
0x3EC JPEG_DHTMEM35 reset not defined — For encoding process with header generation, this memory stores the DHT marker segment AC and DC Huffman tables in the ISO/IEC specification format: - DATA0 to DATA27: DC Huffman table0 - DATA28 to DATA205: AC Huffman table0 - DATA206 to DATA233: DC Huffman table1 - DATA234 to DATA411: AC Huffman table1
  [8n-1113:8n-1120] DATA{n} (n=140..143) — Huffman table data {n} Huffman table data for DHT marker segment generation.
0x3F0 JPEG_DHTMEM36 reset not defined — For encoding process with header generation, this memory stores the DHT marker segment AC and DC Huffman tables in the ISO/IEC specification format: - DATA0 to DATA27: DC Huffman table0 - DATA28 to DATA205: AC Huffman table0 - DATA206 to DATA233: DC Huffman table1 - DATA234 to DATA411: AC Huffman table1
  [8n-1145:8n-1152] DATA{n} (n=144..147) — Huffman table data {n} Huffman table data for DHT marker segment generation.
